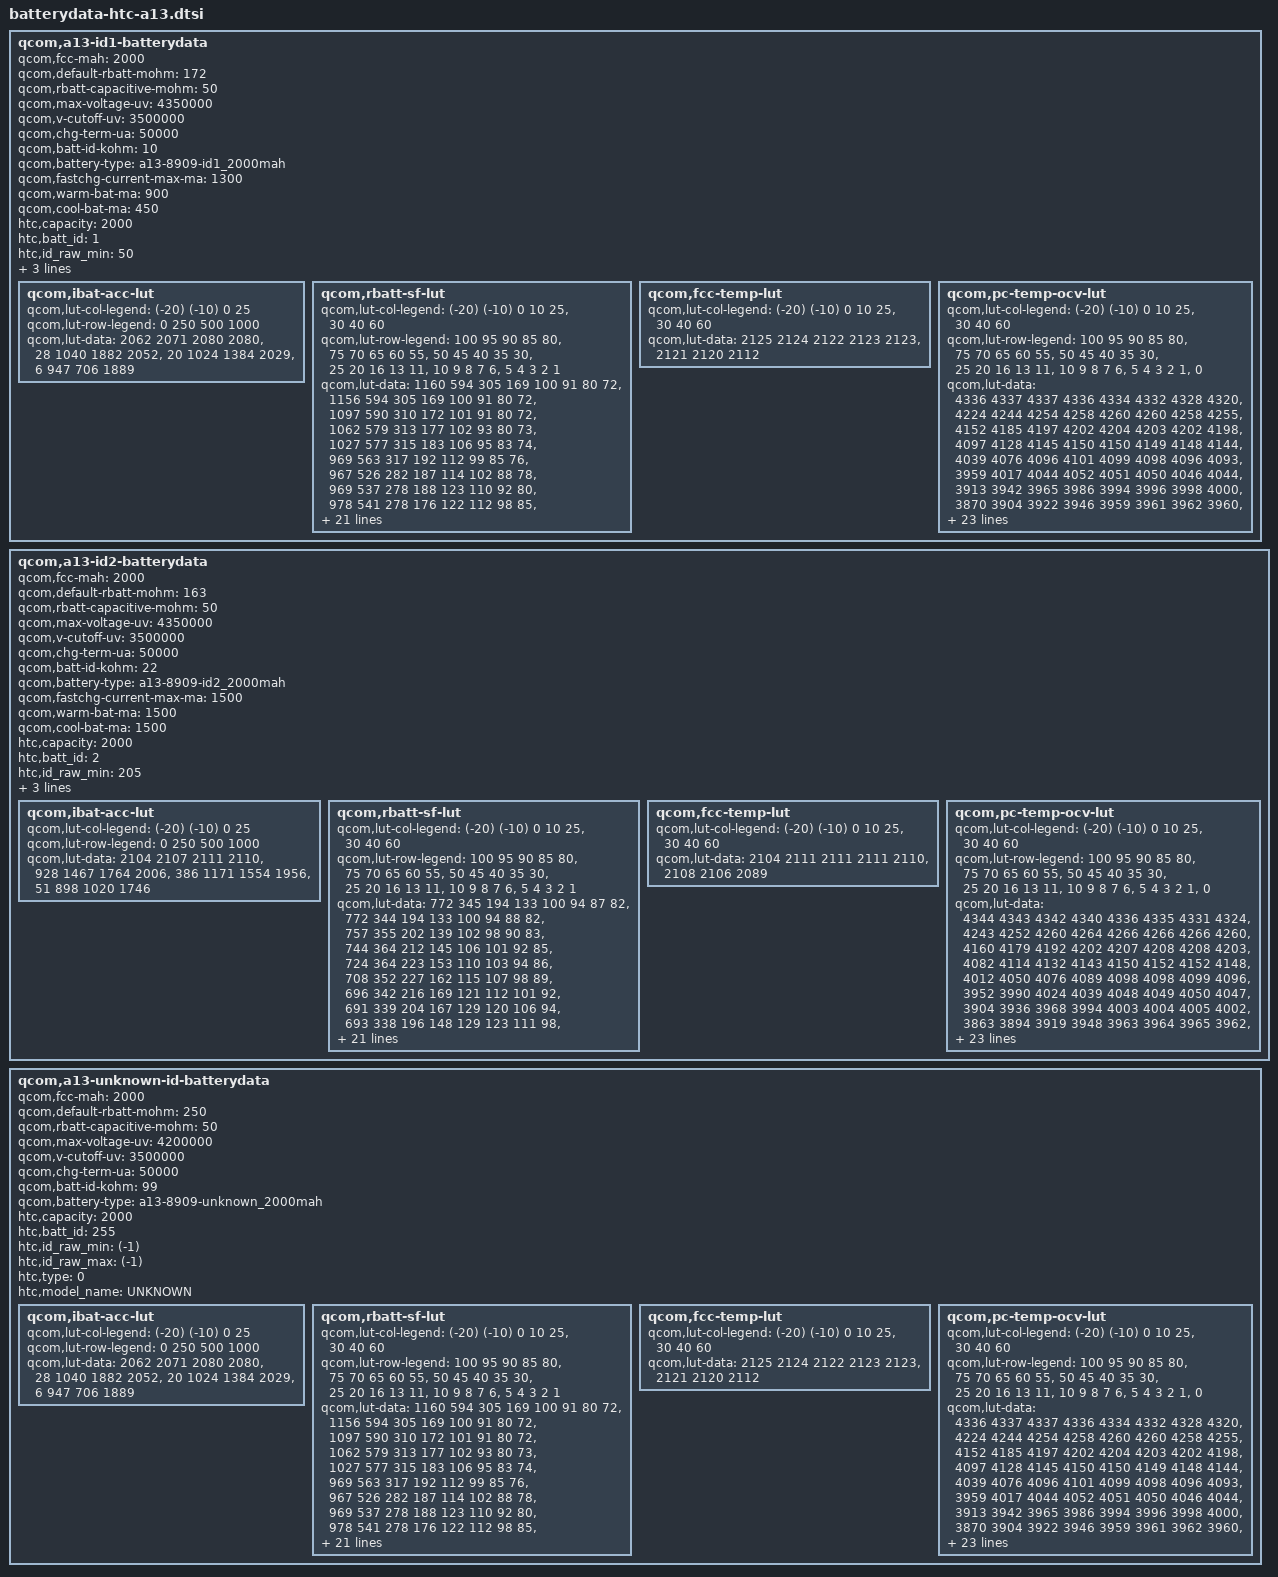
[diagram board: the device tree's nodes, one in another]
/* Copyright (c) 2016, HTC Corporation.
 * Copyright (c) 2026, The LineageOS Project.
 *
 * This program is free software; you can redistribute it and/or modify
 * it under the terms of the GNU General Public License version 2 and
 * only version 2 as published by the Free Software Foundation.
 *
 * This program is distributed in the hope that it will be useful,
 * but WITHOUT ANY WARRANTY; without even the implied warranty of
 * MERCHANTABILITY or FITNESS FOR A PARTICULAR PURPOSE.  See the
 * GNU General Public License for more details.
 */
qcom,a13-id1-batterydata {
	qcom,fcc-mah = <2000>;
	qcom,default-rbatt-mohm = <172>;
	qcom,rbatt-capacitive-mohm = <50>;
	qcom,max-voltage-uv = <4350000>;
	qcom,v-cutoff-uv = <3500000>;
	qcom,chg-term-ua = <50000>;
	qcom,batt-id-kohm = <10>;
	qcom,battery-type = "a13-8909-id1_2000mah";
        qcom,fastchg-current-max-ma = <1300>;
        qcom,warm-bat-ma = <900>;
        qcom,cool-bat-ma = <450>;
	htc,capacity = <2000>;
	htc,batt_id = <1>;
	htc,id_raw_min = <50>;
	htc,id_raw_max = <204>;
	htc,type = <1>;
	htc,model_name = "B0PM3100";

qcom,ibat-acc-lut {
		qcom,lut-col-legend = <(-20) (-10) 0 25>;
		qcom,lut-row-legend = <0 250 500 1000>;
		qcom,lut-data = <2062 2071 2080 2080>,
			<28 1040 1882 2052>,
			<20 1024 1384 2029>,
			<6 947 706 1889>;
	}
;

	qcom,rbatt-sf-lut {
		qcom,lut-col-legend = <(-20) (-10) 0 10 25>,
				<30 40 60>;
		qcom,lut-row-legend = <100 95 90 85 80>,
				<75 70 65 60 55>,
				<50 45 40 35 30>,
				<25 20 16 13 11>,
				<10 9 8 7 6>,
				<5 4 3 2 1>;
		qcom,lut-data = <1160 594 305 169 100 91 80 72>,
				<1156 594 305 169 100 91 80 72>,
				<1097 590 310 172 101 91 80 72>,
				<1062 579 313 177 102 93 80 73>,
				<1027 577 315 183 106 95 83 74>,
				<969 563 317 192 112 99 85 76>,
				<967 526 282 187 114 102 88 78>,
				<969 537 278 188 123 110 92 80>,
				<978 541 278 176 122 112 98 85>,
				<1000 544 276 160 108 101 90 80>,
				<1028 548 276 158 99 90 80 73>,
				<1062 560 279 159 99 91 80 73>,
				<1099 585 287 160 101 92 83 75>,
				<1144 617 304 164 102 94 85 78>,
				<1193 658 321 174 105 95 84 78>,
				<1251 713 337 187 105 94 81 74>,
				<1295 767 338 190 105 94 81 73>,
				<1251 756 343 181 102 93 81 73>,
				<1210 724 338 168 98 90 80 72>,
				<1257 765 356 171 97 89 78 72>,
				<1283 783 369 174 98 90 80 73>,
				<1343 810 382 180 99 91 81 74>,
				<1453 817 397 186 102 93 83 76>,
				<1590 840 414 197 105 95 84 78>,
				<1773 885 426 208 109 99 87 80>,
				<2045 924 434 215 111 99 87 76>,
				<2438 966 447 212 108 97 84 76>,
				<2998 1027 478 219 110 99 86 78>,
				<3948 1183 530 235 120 107 93 85>,
				<6712 1691 609 269 137 124 109 101>;
	};

	qcom,fcc-temp-lut {
		qcom,lut-col-legend = <(-20) (-10) 0 10 25>,
				<30 40 60>;
		qcom,lut-data = <2125 2124 2122 2123 2123>,
				<2121 2120 2112>;
	};

	qcom,pc-temp-ocv-lut {
		qcom,lut-col-legend = <(-20) (-10) 0 10 25>,
				<30 40 60>;
		qcom,lut-row-legend = <100 95 90 85 80>,
				<75 70 65 60 55>,
				<50 45 40 35 30>,
				<25 20 16 13 11>,
				<10 9 8 7 6>,
				<5 4 3 2 1>,
				<0>;
		qcom,lut-data = <4336 4337 4337 4336 4334 4332 4328 4320>,
				<4224 4244 4254 4258 4260 4260 4258 4255>,
				<4152 4185 4197 4202 4204 4203 4202 4198>,
				<4097 4128 4145 4150 4150 4149 4148 4144>,
				<4039 4076 4096 4101 4099 4098 4096 4093>,
				<3959 4017 4044 4052 4051 4050 4046 4044>,
				<3913 3942 3965 3986 3994 3996 3998 4000>,
				<3870 3904 3922 3946 3959 3961 3962 3960>,
				<3838 3873 3892 3907 3920 3922 3924 3922>,
				<3816 3842 3860 3866 3874 3876 3878 3878>,
				<3796 3814 3832 3837 3840 3840 3840 3840>,
				<3778 3791 3808 3814 3816 3817 3818 3816>,
				<3762 3772 3790 3796 3798 3798 3798 3798>,
				<3747 3754 3777 3782 3784 3784 3784 3782>,
				<3734 3740 3764 3772 3772 3771 3769 3764>,
				<3720 3729 3748 3762 3760 3758 3752 3740>,
				<3705 3720 3724 3742 3742 3740 3733 3719>,
				<3688 3712 3710 3720 3720 3718 3712 3699>,
				<3672 3703 3703 3701 3698 3695 3690 3677>,
				<3658 3695 3698 3695 3690 3688 3682 3670>,
				<3650 3690 3696 3692 3688 3686 3681 3670>,
				<3639 3682 3692 3690 3687 3685 3680 3668>,
				<3627 3676 3689 3689 3685 3684 3679 3667>,
				<3612 3664 3685 3687 3684 3682 3677 3665>,
				<3594 3647 3676 3682 3680 3678 3672 3659>,
				<3570 3626 3656 3668 3664 3664 3656 3636>,
				<3539 3594 3624 3633 3626 3622 3615 3592>,
				<3496 3550 3576 3580 3568 3564 3555 3534>,
				<3436 3486 3506 3506 3490 3486 3476 3452>,
				<3332 3382 3396 3391 3370 3362 3350 3320>,
				<3000 3000 3000 3000 3000 3000 3000 3000>;
	};
};

qcom,a13-id2-batterydata {
	qcom,fcc-mah = <2000>;
	qcom,default-rbatt-mohm = <163>;
	qcom,rbatt-capacitive-mohm = <50>;
	qcom,max-voltage-uv = <4350000>;
	qcom,v-cutoff-uv = <3500000>;
	qcom,chg-term-ua = <50000>;
	qcom,batt-id-kohm = <22>;
	qcom,battery-type = "a13-8909-id2_2000mah";
        qcom,fastchg-current-max-ma = <1500>;
        qcom,warm-bat-ma = <1500>;
        qcom,cool-bat-ma = <1500>;
	htc,capacity = <2000>;
	htc,batt_id = <2>;
	htc,id_raw_min = <205>;
	htc,id_raw_max = <385>;
	htc,type = <1>;
	htc,model_name = "B0PM3100";

qcom,ibat-acc-lut {
		qcom,lut-col-legend = <(-20) (-10) 0 25>;
		qcom,lut-row-legend = <0 250 500 1000>;
		qcom,lut-data = <2104 2107 2111 2110>,
			<928 1467 1764 2006>,
			<386 1171 1554 1956>,
			<51 898 1020 1746>;
	}
;

	qcom,rbatt-sf-lut {
		qcom,lut-col-legend = <(-20) (-10) 0 10 25>,
				<30 40 60>;
		qcom,lut-row-legend = <100 95 90 85 80>,
				<75 70 65 60 55>,
				<50 45 40 35 30>,
				<25 20 16 13 11>,
				<10 9 8 7 6>,
				<5 4 3 2 1>;
		qcom,lut-data = <772 345 194 133 100 94 87 82>,
				<772 344 194 133 100 94 88 82>,
				<757 355 202 139 102 98 90 83>,
				<744 364 212 145 106 101 92 85>,
				<724 364 223 153 110 103 94 86>,
				<708 352 227 162 115 107 98 89>,
				<696 342 216 169 121 112 101 92>,
				<691 339 204 167 129 120 106 94>,
				<693 338 196 148 129 123 111 98>,
				<701 339 195 137 112 108 102 93>,
				<723 340 194 134 102 96 90 85>,
				<766 342 196 136 102 98 91 87>,
				<836 350 199 139 104 99 94 90>,
				<960 369 208 140 107 101 97 93>,
				<1163 421 222 147 109 102 94 89>,
				<1395 582 241 158 109 101 91 86>,
				<1854 890 274 161 106 98 91 87>,
				<2477 1050 361 160 106 99 91 86>,
				<3039 1137 477 162 99 94 87 83>,
				<4144 1298 637 185 104 97 90 86>,
				<4944 1400 733 208 107 100 92 87>,
				<5986 1638 836 244 110 103 94 89>,
				<7401 1975 937 296 115 106 96 90>,
				<9201 2390 1052 374 120 109 99 92>,
				<11915 2950 1171 466 125 112 100 92>,
				<15596 3734 1318 566 126 112 96 88>,
				<21393 4909 1623 679 128 111 97 91>,
				<33301 6768 2164 821 140 118 102 93>,
				<52087 9944 3094 1028 163 129 109 98>,
				<83427 15762 4811 1477 212 156 134 115>;
	};

	qcom,fcc-temp-lut {
		qcom,lut-col-legend = <(-20) (-10) 0 10 25>,
				<30 40 60>;
		qcom,lut-data = <2104 2111 2111 2111 2110>,
				<2108 2106 2089>;
	};

	qcom,pc-temp-ocv-lut {
		qcom,lut-col-legend = <(-20) (-10) 0 10 25>,
				<30 40 60>;
		qcom,lut-row-legend = <100 95 90 85 80>,
				<75 70 65 60 55>,
				<50 45 40 35 30>,
				<25 20 16 13 11>,
				<10 9 8 7 6>,
				<5 4 3 2 1>,
				<0>;
		qcom,lut-data = <4344 4343 4342 4340 4336 4335 4331 4324>,
				<4243 4252 4260 4264 4266 4266 4266 4260>,
				<4160 4179 4192 4202 4207 4208 4208 4203>,
				<4082 4114 4132 4143 4150 4152 4152 4148>,
				<4012 4050 4076 4089 4098 4098 4099 4096>,
				<3952 3990 4024 4039 4048 4049 4050 4047>,
				<3904 3936 3968 3994 4003 4004 4005 4002>,
				<3863 3894 3919 3948 3963 3964 3965 3962>,
				<3829 3858 3879 3899 3920 3923 3926 3924>,
				<3801 3829 3847 3859 3874 3876 3880 3880>,
				<3780 3802 3820 3830 3838 3839 3841 3841>,
				<3764 3780 3798 3807 3814 3816 3818 3818>,
				<3749 3762 3780 3789 3796 3797 3799 3799>,
				<3734 3746 3768 3775 3781 3782 3783 3783>,
				<3719 3730 3758 3764 3770 3769 3768 3762>,
				<3700 3713 3742 3755 3756 3754 3750 3738>,
				<3678 3695 3716 3733 3735 3733 3728 3716>,
				<3652 3682 3685 3700 3706 3705 3701 3688>,
				<3623 3670 3668 3674 3679 3678 3676 3665>,
				<3598 3660 3660 3665 3673 3673 3671 3662>,
				<3583 3654 3656 3660 3670 3671 3669 3660>,
				<3566 3647 3651 3656 3667 3668 3667 3659>,
				<3544 3638 3646 3651 3663 3665 3664 3656>,
				<3517 3626 3641 3646 3658 3660 3660 3652>,
				<3484 3610 3632 3638 3649 3651 3651 3638>,
				<3439 3588 3612 3620 3626 3627 3625 3606>,
				<3378 3556 3577 3581 3580 3578 3575 3556>,
				<3298 3510 3523 3522 3516 3514 3513 3491>,
				<3216 3438 3444 3442 3432 3428 3422 3402>,
				<3145 3322 3324 3319 3302 3296 3285 3261>,
				<3000 3000 3000 3000 3000 3000 3000 3000>;
	};
};

qcom,a13-unknown-id-batterydata {
	qcom,fcc-mah = <2000>;
	qcom,default-rbatt-mohm = <250>;
	qcom,rbatt-capacitive-mohm = <50>;
	qcom,max-voltage-uv = <4200000>;
	qcom,v-cutoff-uv = <3500000>;
	qcom,chg-term-ua = <50000>;
	qcom,batt-id-kohm = <99>;
	qcom,battery-type = "a13-8909-unknown_2000mah";
	htc,capacity = <2000>;
	htc,batt_id = <255>;
	htc,id_raw_min = <(-1)>;
	htc,id_raw_max = <(-1)>;
	htc,type = <0>;
	htc,model_name = "UNKNOWN";

qcom,ibat-acc-lut {
		qcom,lut-col-legend = <(-20) (-10) 0 25>;
		qcom,lut-row-legend = <0 250 500 1000>;
		qcom,lut-data = <2062 2071 2080 2080>,
			<28 1040 1882 2052>,
			<20 1024 1384 2029>,
			<6 947 706 1889>;
	}
;

	qcom,rbatt-sf-lut {
		qcom,lut-col-legend = <(-20) (-10) 0 10 25>,
				<30 40 60>;
		qcom,lut-row-legend = <100 95 90 85 80>,
				<75 70 65 60 55>,
				<50 45 40 35 30>,
				<25 20 16 13 11>,
				<10 9 8 7 6>,
				<5 4 3 2 1>;
		qcom,lut-data = <1160 594 305 169 100 91 80 72>,
				<1156 594 305 169 100 91 80 72>,
				<1097 590 310 172 101 91 80 72>,
				<1062 579 313 177 102 93 80 73>,
				<1027 577 315 183 106 95 83 74>,
				<969 563 317 192 112 99 85 76>,
				<967 526 282 187 114 102 88 78>,
				<969 537 278 188 123 110 92 80>,
				<978 541 278 176 122 112 98 85>,
				<1000 544 276 160 108 101 90 80>,
				<1028 548 276 158 99 90 80 73>,
				<1062 560 279 159 99 91 80 73>,
				<1099 585 287 160 101 92 83 75>,
				<1144 617 304 164 102 94 85 78>,
				<1193 658 321 174 105 95 84 78>,
				<1251 713 337 187 105 94 81 74>,
				<1295 767 338 190 105 94 81 73>,
				<1251 756 343 181 102 93 81 73>,
				<1210 724 338 168 98 90 80 72>,
				<1257 765 356 171 97 89 78 72>,
				<1283 783 369 174 98 90 80 73>,
				<1343 810 382 180 99 91 81 74>,
				<1453 817 397 186 102 93 83 76>,
				<1590 840 414 197 105 95 84 78>,
				<1773 885 426 208 109 99 87 80>,
				<2045 924 434 215 111 99 87 76>,
				<2438 966 447 212 108 97 84 76>,
				<2998 1027 478 219 110 99 86 78>,
				<3948 1183 530 235 120 107 93 85>,
				<6712 1691 609 269 137 124 109 101>;
	};

	qcom,fcc-temp-lut {
		qcom,lut-col-legend = <(-20) (-10) 0 10 25>,
				<30 40 60>;
		qcom,lut-data = <2125 2124 2122 2123 2123>,
				<2121 2120 2112>;
	};

	qcom,pc-temp-ocv-lut {
		qcom,lut-col-legend = <(-20) (-10) 0 10 25>,
				<30 40 60>;
		qcom,lut-row-legend = <100 95 90 85 80>,
				<75 70 65 60 55>,
				<50 45 40 35 30>,
				<25 20 16 13 11>,
				<10 9 8 7 6>,
				<5 4 3 2 1>,
				<0>;
		qcom,lut-data = <4336 4337 4337 4336 4334 4332 4328 4320>,
				<4224 4244 4254 4258 4260 4260 4258 4255>,
				<4152 4185 4197 4202 4204 4203 4202 4198>,
				<4097 4128 4145 4150 4150 4149 4148 4144>,
				<4039 4076 4096 4101 4099 4098 4096 4093>,
				<3959 4017 4044 4052 4051 4050 4046 4044>,
				<3913 3942 3965 3986 3994 3996 3998 4000>,
				<3870 3904 3922 3946 3959 3961 3962 3960>,
				<3838 3873 3892 3907 3920 3922 3924 3922>,
				<3816 3842 3860 3866 3874 3876 3878 3878>,
				<3796 3814 3832 3837 3840 3840 3840 3840>,
				<3778 3791 3808 3814 3816 3817 3818 3816>,
				<3762 3772 3790 3796 3798 3798 3798 3798>,
				<3747 3754 3777 3782 3784 3784 3784 3782>,
				<3734 3740 3764 3772 3772 3771 3769 3764>,
				<3720 3729 3748 3762 3760 3758 3752 3740>,
				<3705 3720 3724 3742 3742 3740 3733 3719>,
				<3688 3712 3710 3720 3720 3718 3712 3699>,
				<3672 3703 3703 3701 3698 3695 3690 3677>,
				<3658 3695 3698 3695 3690 3688 3682 3670>,
				<3650 3690 3696 3692 3688 3686 3681 3670>,
				<3639 3682 3692 3690 3687 3685 3680 3668>,
				<3627 3676 3689 3689 3685 3684 3679 3667>,
				<3612 3664 3685 3687 3684 3682 3677 3665>,
				<3594 3647 3676 3682 3680 3678 3672 3659>,
				<3570 3626 3656 3668 3664 3664 3656 3636>,
				<3539 3594 3624 3633 3626 3622 3615 3592>,
				<3496 3550 3576 3580 3568 3564 3555 3534>,
				<3436 3486 3506 3506 3490 3486 3476 3452>,
				<3332 3382 3396 3391 3370 3362 3350 3320>,
				<3000 3000 3000 3000 3000 3000 3000 3000>;
	};
};
